AUTOSAR XML (schema 4.0)
package /ADAS_Components
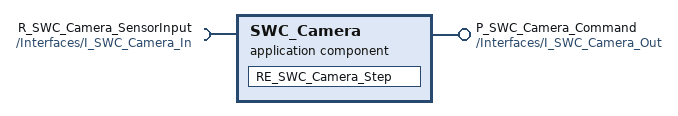
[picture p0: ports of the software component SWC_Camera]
  application sw component type SWC_Camera  # AUTOSAR Application SWC SWC_Camera for ADAS control
    provide port P_SWC_Camera_Command: provided-interface=/Interfaces/I_SWC_Camera_Out
    require port R_SWC_Camera_SensorInput: required-interface=/Interfaces/I_SWC_Camera_In
    behavior SWC_Camera_Behavior
      runnable RE_SWC_Camera_Step: symbol=SWC_Camera_Step
